# HC32F472 register map
File version: 1.0
CPU: CM4 r0p1, little endian, MPU, FPU, 4 interrupt priority bits
Registers are 32-bit, read-write, reset 0x0 unless marked. A register's access mark holds for its fields unless they carry their own. Offsets are from the block's base; [hi:lo] are bit positions; {n}, {i} and the like mark numbered series.

## ADC1
Base 0x40040000
Same registers: ADC2 0x40040400
0x00 STR 8-bit
  [0] STRT
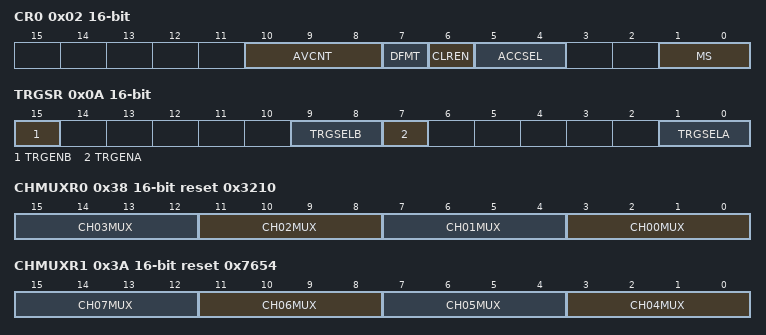
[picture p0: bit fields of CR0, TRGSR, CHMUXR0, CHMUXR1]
0x02 CR0 16-bit
  [10:8] AVCNT, [7] DFMT, [6] CLREN, [5:4] ACCSEL, [1:0] MS
0x04 CR1 16-bit
  [2] RSCHSEL
0x0A TRGSR 16-bit
  [15] TRGENB, [9:8] TRGSELB, [7] TRGENA, [1:0] TRGSELA
0x0C CHSELRA
  [23:0] CHSELA
0x10 CHSELRB
  [23:0] CHSELB
0x14 AVCHSELR
  [23:0] AVCHSEL
{0x20+i} SSTR{i} 8-bit reset 0xB (i=0..15)
0x30 SSTRL 8-bit reset 0xB
0x38 CHMUXR0 16-bit reset 0x3210
  [4n+3:4n] CH{n:02}MUX (n=0..3)
0x3A CHMUXR1 16-bit reset 0x7654
  [4n-13:4n-16] CH{n:02}MUX (n=4..7)
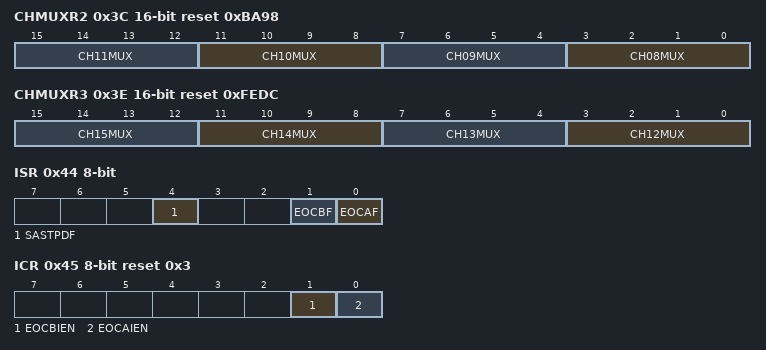
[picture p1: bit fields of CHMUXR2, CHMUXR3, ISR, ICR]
0x3C CHMUXR2 16-bit reset 0xBA98
  [4n-29:4n-32] CH{n:02}MUX (n=8..11)
0x3E CHMUXR3 16-bit reset 0xFEDC
  [4n-45:4n-48] CH{n}MUX (n=12..15)
0x44 ISR 8-bit ro
  [4] SASTPDF, [1] EOCBF, [0] EOCAF
0x45 ICR 8-bit reset 0x3
  [1] EOCBIEN, [0] EOCAIEN
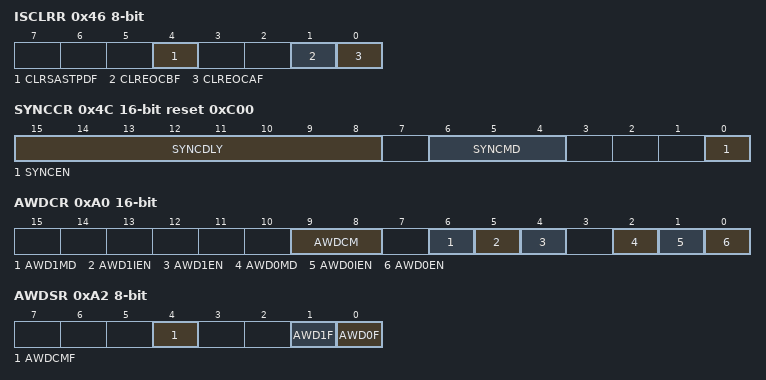
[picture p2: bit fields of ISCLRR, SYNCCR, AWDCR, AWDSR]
0x46 ISCLRR 8-bit
  [4] CLRSASTPDF, [1] CLREOCBF, [0] CLREOCAF
0x4C SYNCCR 16-bit reset 0xC00
  [15:8] SYNCDLY, [6:4] SYNCMD, [0] SYNCEN
{0x50+2i} DR{i} 16-bit ro (i=0..23)
0xA0 AWDCR 16-bit
  [9:8] AWDCM, [6] AWD1MD, [5] AWD1IEN, [4] AWD1EN, [2] AWD0MD, [1] AWD0IEN, [0] AWD0EN
0xA2 AWDSR 8-bit ro
  [4] AWDCMF, [1] AWD1F, [0] AWD0F
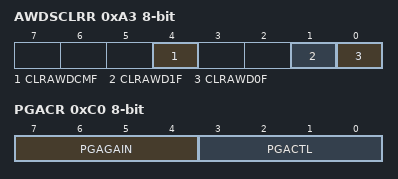
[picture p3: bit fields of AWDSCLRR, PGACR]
0xA3 AWDSCLRR 8-bit
  [4] CLRAWDCMF, [1] CLRAWD1F, [0] CLRAWD0F
0xA4 AWD0DR0 16-bit
0xA6 AWD0DR1 16-bit reset 0xFFFF
0xA8 AWD0CHSR 8-bit
  [4:0] AWDCH
0xAC AWD1DR0 16-bit
0xAE AWD1DR1 16-bit reset 0xFFFF
0xB0 AWD1CHSR 8-bit
  [4:0] AWDCH
0xC0 PGACR 8-bit
  [7:4] PGAGAIN, [3:0] PGACTL
0xC4 PGAVSSENR 8-bit
  [0] PGAVSSEN

## ADC3
Base 0x40040800
Registers as ADC1, without PGACR, PGAVSSENR; these are added or differ:
0x0C CHSELRA
  [24:0] CHSELA
0x10 CHSELRB
  [24:0] CHSELB
0x14 AVCHSELR
  [24:0] AVCHSEL
0x80 DR24 16-bit ro

## AES
Base 0x40008000
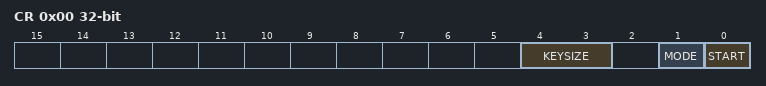
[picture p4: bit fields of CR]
0x00 CR
  [4:3] KEYSIZE, [1] MODE, [0] START
{0x10+4i} DR{i} (i=0..3)
{0x20+4i} KR{i} (i=0..7)

## AOS
Base 0x40010800
0x00 INTSFTTRG wo
  [0] STRG
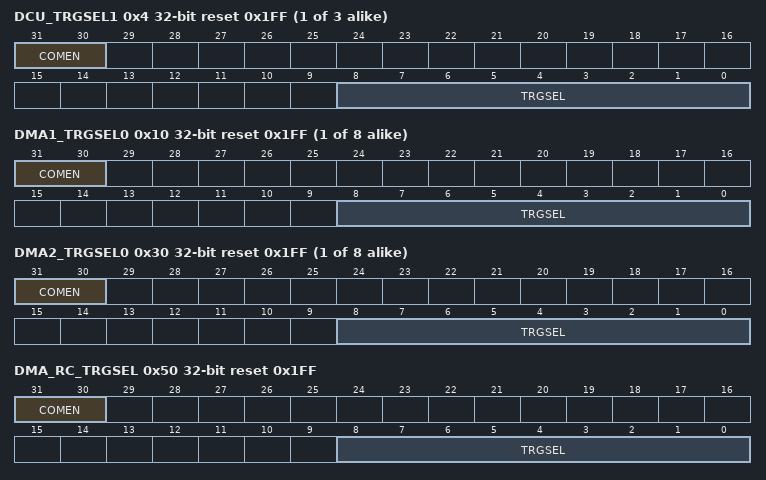
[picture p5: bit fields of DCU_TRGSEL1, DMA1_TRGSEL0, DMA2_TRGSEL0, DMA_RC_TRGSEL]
{0x0+4i} DCU_TRGSEL{i} reset 0x1FF (i=1..3)
  [31:30] COMEN, [8:0] TRGSEL
{0x10+4i} DMA1_TRGSEL{i} reset 0x1FF (i=0..7)
  [31:30] COMEN, [8:0] TRGSEL
{0x30+4i} DMA2_TRGSEL{i} reset 0x1FF (i=0..7)
  [31:30] COMEN, [8:0] TRGSEL
0x50 DMA_RC_TRGSEL reset 0x1FF
  [31:30] COMEN, [8:0] TRGSEL
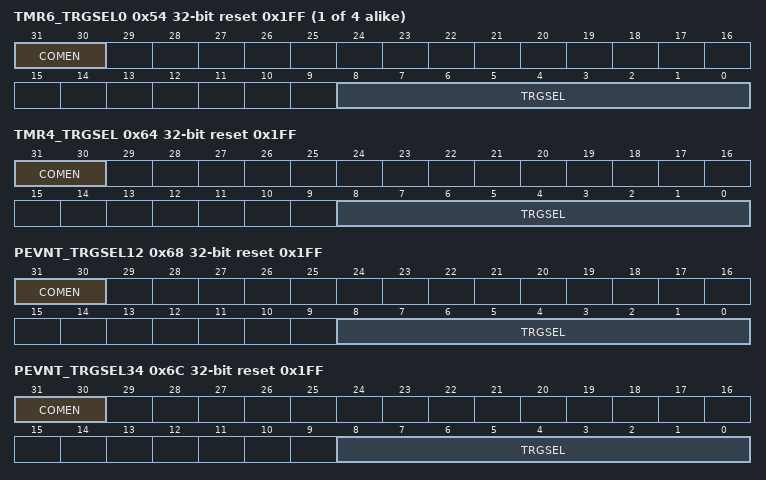
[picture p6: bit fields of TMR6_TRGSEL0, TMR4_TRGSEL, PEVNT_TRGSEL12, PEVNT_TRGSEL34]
{0x54+4i} TMR6_TRGSEL{i} reset 0x1FF (i=0..3)
  [31:30] COMEN, [8:0] TRGSEL
0x64 TMR4_TRGSEL reset 0x1FF
  [31:30] COMEN, [8:0] TRGSEL
0x68 PEVNT_TRGSEL12 reset 0x1FF
  [31:30] COMEN, [8:0] TRGSEL
0x6C PEVNT_TRGSEL34 reset 0x1FF
  [31:30] COMEN, [8:0] TRGSEL
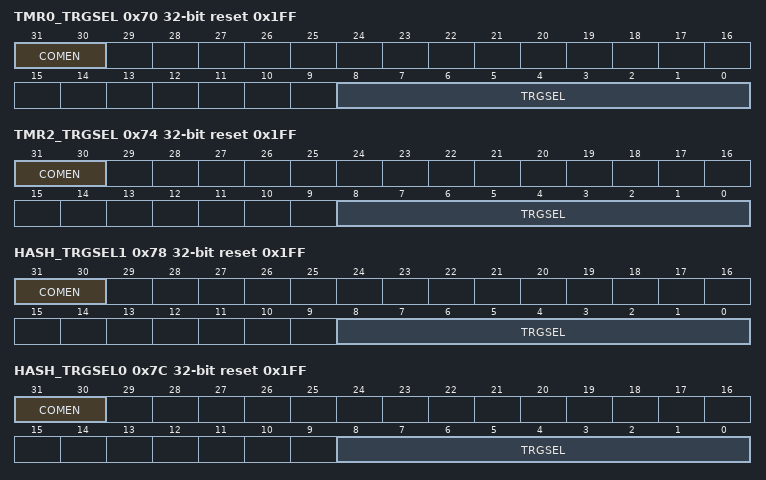
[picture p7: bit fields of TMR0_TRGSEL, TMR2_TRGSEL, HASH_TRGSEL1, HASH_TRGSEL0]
0x70 TMR0_TRGSEL reset 0x1FF
  [31:30] COMEN, [8:0] TRGSEL
0x74 TMR2_TRGSEL reset 0x1FF
  [31:30] COMEN, [8:0] TRGSEL
0x78 HASH_TRGSEL1 reset 0x1FF
  [31:30] COMEN, [8:0] TRGSEL
0x7C HASH_TRGSEL0 reset 0x1FF
  [31:30] COMEN, [8:0] TRGSEL
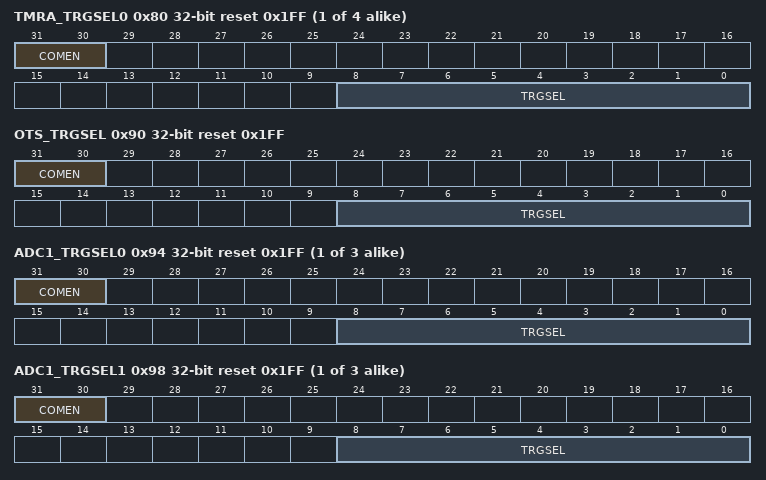
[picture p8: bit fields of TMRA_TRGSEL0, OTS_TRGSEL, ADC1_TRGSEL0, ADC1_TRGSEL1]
{0x80+4i} TMRA_TRGSEL{i} reset 0x1FF (i=0..3)
  [31:30] COMEN, [8:0] TRGSEL
0x90 OTS_TRGSEL reset 0x1FF
  [31:30] COMEN, [8:0] TRGSEL
{0x8C+8i} ADC{i}_TRGSEL0 reset 0x1FF (i=1..3)
  [31:30] COMEN, [8:0] TRGSEL
{0x90+8i} ADC{i}_TRGSEL1 reset 0x1FF (i=1..3)
  [31:30] COMEN, [8:0] TRGSEL
0xAC COMTRGSEL1 reset 0x1FF
  [8:0] COMTRG
0xB0 COMTRGSEL2 reset 0x1FF
  [8:0] COMTRG
{0xE4+0x1C*i} PEVNTDIRR{i} (i=1..4)
  [15:0] PDIR
{0xE8+0x1C*i} PEVNTIDR{i} ro (i=1..4)
  [15:0] PIN
{0xEC+0x1C*i} PEVNTODR{i} (i=1..4)
  [15:0] POUT
{0xF0+0x1C*i} PEVNTORR{i} (i=1..4)
  [15:0] POR
{0xF4+0x1C*i} PEVNTOSR{i} (i=1..4)
  [15:0] POS
{0xF8+0x1C*i} PEVNTRISR{i} (i=1..4)
  [15:0] RIS
{0xFC+0x1C*i} PEVNTFALR{i} (i=1..4)
  [15:0] FAL
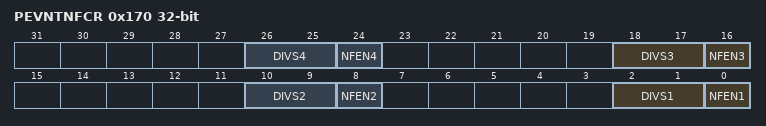
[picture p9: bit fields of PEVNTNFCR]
0x170 PEVNTNFCR
  [8n-6:8n-7] DIVS{n} (n=1..4), [8n-8] NFEN{n} (n=1..4)

## CAN1 — desc CAN
Base 0x40078000
Same registers: CAN3 0x40071000, CAN2 0x40071400
0x00 RBUF ro
0x50 TBUF
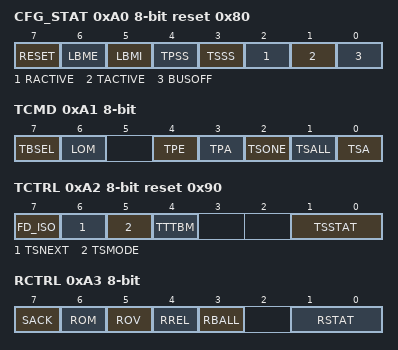
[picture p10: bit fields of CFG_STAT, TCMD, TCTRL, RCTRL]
0xA0 CFG_STAT 8-bit reset 0x80
  [7] RESET, [6] LBME, [5] LBMI, [4] TPSS, [3] TSSS, [2] RACTIVE ro, [1] TACTIVE ro, [0] BUSOFF
0xA1 TCMD 8-bit
  [7] TBSEL, [6] LOM, [4] TPE, [3] TPA, [2] TSONE, [1] TSALL, [0] TSA
0xA2 TCTRL 8-bit reset 0x90
  [7] FD_ISO, [6] TSNEXT, [5] TSMODE, [4] TTTBM, [1:0] TSSTAT ro
0xA3 RCTRL 8-bit
  [7] SACK, [6] ROM, [5] ROV ro, [4] RREL, [3] RBALL, [1:0] RSTAT ro
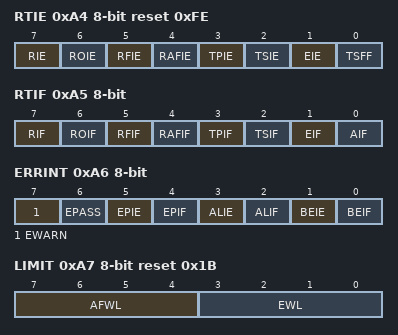
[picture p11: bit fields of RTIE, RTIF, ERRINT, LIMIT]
0xA4 RTIE 8-bit reset 0xFE
  [7] RIE, [6] ROIE, [5] RFIE, [4] RAFIE, [3] TPIE, [2] TSIE, [1] EIE, [0] TSFF ro
0xA5 RTIF 8-bit
  [7] RIF, [6] ROIF, [5] RFIF, [4] RAFIF, [3] TPIF, [2] TSIF, [1] EIF, [0] AIF
0xA6 ERRINT 8-bit
  [7] EWARN ro, [6] EPASS ro, [5] EPIE, [4] EPIF, [3] ALIE, [2] ALIF, [1] BEIE, [0] BEIF
0xA7 LIMIT 8-bit reset 0x1B
  [7:4] AFWL, [3:0] EWL
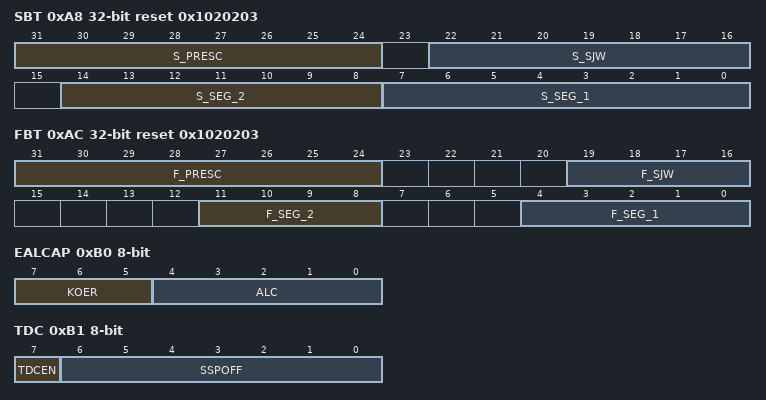
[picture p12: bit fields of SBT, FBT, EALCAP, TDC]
0xA8 SBT reset 0x1020203
  [31:24] S_PRESC, [22:16] S_SJW, [14:8] S_SEG_2, [7:0] S_SEG_1
0xAC FBT reset 0x1020203
  [31:24] F_PRESC, [19:16] F_SJW, [11:8] F_SEG_2, [4:0] F_SEG_1
0xB0 EALCAP 8-bit ro
  [7:5] KOER, [4:0] ALC
0xB1 TDC 8-bit
  [7] TDCEN, [6:0] SSPOFF
0xB2 RECNT 8-bit
0xB3 TECNT 8-bit
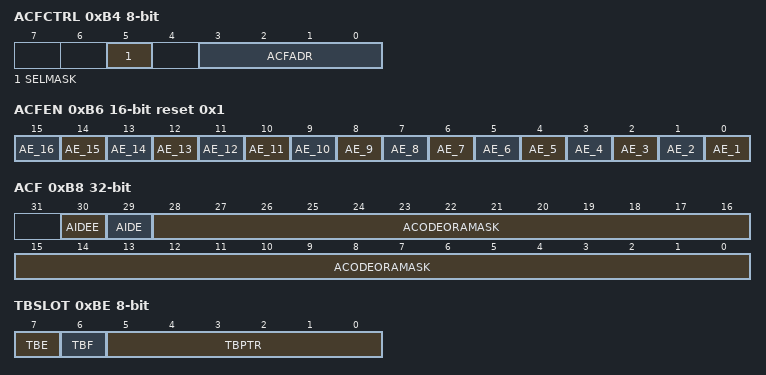
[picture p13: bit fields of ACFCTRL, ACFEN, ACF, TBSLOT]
0xB4 ACFCTRL 8-bit
  [5] SELMASK, [3:0] ACFADR
0xB6 ACFEN 16-bit reset 0x1
  [n-1] AE_{n} (n=1..16)
0xB8 ACF
  [30] AIDEE, [29] AIDE, [28:0] ACODEORAMASK
0xBE TBSLOT 8-bit
  [7] TBE, [6] TBF, [5:0] TBPTR
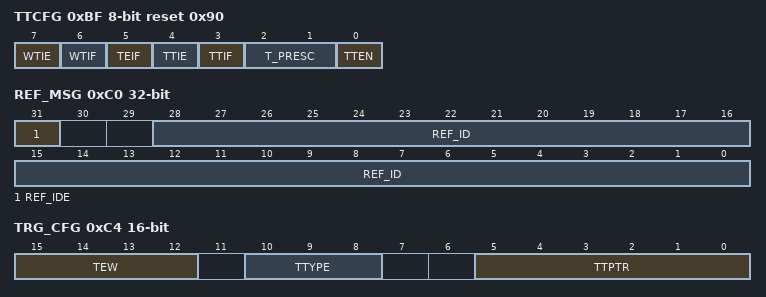
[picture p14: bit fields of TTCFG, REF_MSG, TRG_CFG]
0xBF TTCFG 8-bit reset 0x90
  [7] WTIE, [6] WTIF, [5] TEIF, [4] TTIE, [3] TTIF, [2:1] T_PRESC, [0] TTEN
0xC0 REF_MSG
  [31] REF_IDE, [28:0] REF_ID
0xC4 TRG_CFG 16-bit
  [15:12] TEW, [10:8] TTYPE, [5:0] TTPTR
0xC6 TT_TRIG 16-bit
0xC8 TT_WTRIG 16-bit reset 0xFFFF
